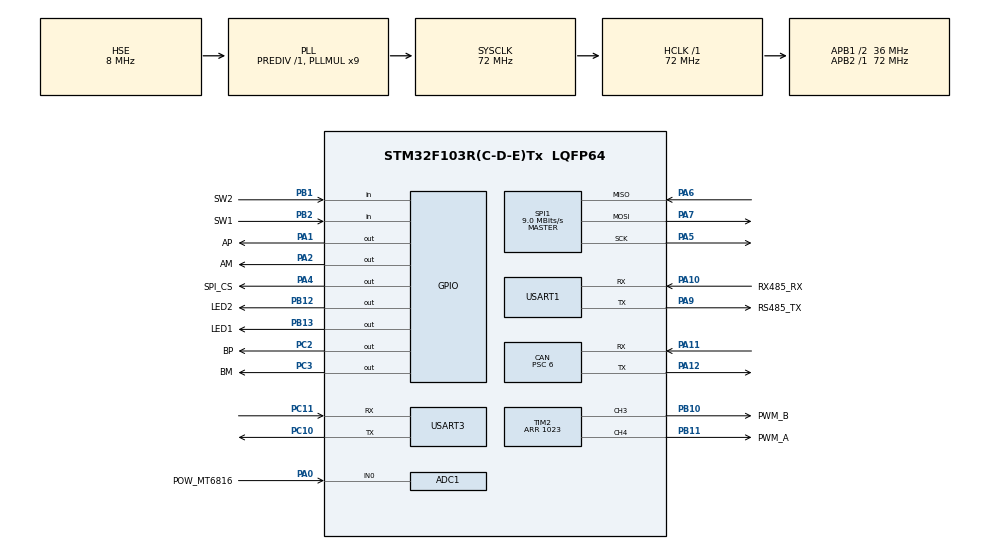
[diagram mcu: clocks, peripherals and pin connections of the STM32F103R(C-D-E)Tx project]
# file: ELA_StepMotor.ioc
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ADC1.Channel-0\#ChannelRegularConversion=ADC_CHANNEL_0
ADC1.NbrOfConversionFlag=1
ADC1.Rank-0\#ChannelRegularConversion=1
ADC1.SamplingTime-0\#ChannelRegularConversion=ADC_SAMPLETIME_1CYCLE_5
ADC1.master=1
CAN.BS1=CAN_BS1_9TQ
CAN.BS2=CAN_BS2_2TQ
CAN.CalculateBaudRate=499999
CAN.CalculateTimeBit=2000
CAN.CalculateTimeQuantum=166.66666666666669
CAN.Prescaler=6
CAN.SJW=CAN_SJW_1TQ
Dma.ADC1.0.Direction=DMA_PERIPH_TO_MEMORY
Dma.ADC1.0.Instance=DMA1_Channel1
Dma.ADC1.0.MemDataAlignment=DMA_MDATAALIGN_HALFWORD
Dma.ADC1.0.MemInc=DMA_MINC_ENABLE
Dma.ADC1.0.Mode=DMA_CIRCULAR
Dma.ADC1.0.PeriphDataAlignment=DMA_PDATAALIGN_HALFWORD
Dma.ADC1.0.PeriphInc=DMA_PINC_DISABLE
Dma.ADC1.0.Priority=DMA_PRIORITY_VERY_HIGH
Dma.Request0=ADC1
Dma.Request1=USART3_RX
Dma.Request2=USART3_TX
Dma.Request3=USART1_RX
Dma.Request4=USART1_TX
Dma.USART1_RX.3.Direction=DMA_PERIPH_TO_MEMORY
Dma.USART1_RX.3.Instance=DMA1_Channel5
Dma.USART1_RX.3.MemDataAlignment=DMA_MDATAALIGN_BYTE
Dma.USART1_RX.3.MemInc=DMA_MINC_ENABLE
Dma.USART1_RX.3.Mode=DMA_CIRCULAR
Dma.USART1_RX.3.PeriphDataAlignment=DMA_PDATAALIGN_BYTE
Dma.USART1_RX.3.PeriphInc=DMA_PINC_DISABLE
Dma.USART1_RX.3.Priority=DMA_PRIORITY_HIGH
Dma.USART1_TX.4.Direction=DMA_MEMORY_TO_PERIPH
Dma.USART1_TX.4.Instance=DMA1_Channel4
Dma.USART1_TX.4.MemDataAlignment=DMA_MDATAALIGN_BYTE
Dma.USART1_TX.4.MemInc=DMA_MINC_ENABLE
Dma.USART1_TX.4.Mode=DMA_NORMAL
Dma.USART1_TX.4.PeriphDataAlignment=DMA_PDATAALIGN_BYTE
Dma.USART1_TX.4.PeriphInc=DMA_PINC_DISABLE
Dma.USART1_TX.4.Priority=DMA_PRIORITY_HIGH
Dma.USART3_RX.1.Direction=DMA_PERIPH_TO_MEMORY
Dma.USART3_RX.1.Instance=DMA1_Channel3
Dma.USART3_RX.1.MemDataAlignment=DMA_MDATAALIGN_BYTE
Dma.USART3_RX.1.MemInc=DMA_MINC_ENABLE
Dma.USART3_RX.1.Mode=DMA_CIRCULAR
Dma.USART3_RX.1.PeriphDataAlignment=DMA_PDATAALIGN_BYTE
Dma.USART3_RX.1.PeriphInc=DMA_PINC_DISABLE
Dma.USART3_RX.1.Priority=DMA_PRIORITY_VERY_HIGH
Dma.USART3_TX.2.Direction=DMA_MEMORY_TO_PERIPH
Dma.USART3_TX.2.Instance=DMA1_Channel2
Dma.USART3_TX.2.MemDataAlignment=DMA_MDATAALIGN_BYTE
Dma.USART3_TX.2.MemInc=DMA_MINC_ENABLE
Dma.USART3_TX.2.Mode=DMA_NORMAL
Dma.USART3_TX.2.PeriphDataAlignment=DMA_PDATAALIGN_BYTE
Dma.USART3_TX.2.PeriphInc=DMA_PINC_DISABLE
Dma.USART3_TX.2.Priority=DMA_PRIORITY_HIGH
Mcu.Family=STM32F1
Mcu.Name=STM32F103R(C-D-E)Tx
Mcu.Package=LQFP64
NVIC.CAN1_RX1_IRQn=true\:0\:0\:false\:false\:true\:true\:true\:true
NVIC.CAN1_SCE_IRQn=true\:0\:0\:false\:false\:true\:true\:true\:true
NVIC.DMA1_Channel1_IRQn=true\:0\:0\:false\:false\:true\:false\:true\:true
NVIC.DMA1_Channel2_IRQn=true\:0\:0\:false\:false\:true\:false\:true\:true
NVIC.DMA1_Channel3_IRQn=true\:0\:0\:false\:false\:true\:false\:true\:true
NVIC.DMA1_Channel4_IRQn=true\:0\:0\:false\:false\:true\:false\:true\:true
NVIC.DMA1_Channel5_IRQn=true\:0\:0\:false\:false\:true\:false\:true\:true
NVIC.PriorityGroup=NVIC_PRIORITYGROUP_4
NVIC.TIM1_UP_IRQn=true\:0\:0\:false\:false\:true\:true\:true\:true
NVIC.TIM3_IRQn=true\:2\:0\:true\:false\:true\:true\:true\:true
NVIC.TIM4_IRQn=true\:0\:0\:false\:false\:true\:true\:true\:true
NVIC.USART1_IRQn=true\:0\:0\:false\:false\:true\:true\:true\:true
NVIC.USART3_IRQn=true\:0\:0\:false\:false\:true\:true\:true\:true
NVIC.USB_HP_CAN1_TX_IRQn=true\:0\:0\:false\:false\:true\:true\:true\:true
NVIC.USB_LP_CAN1_RX0_IRQn=true\:0\:0\:false\:false\:true\:true\:true\:true
PA0-WKUP.GPIO_Label=POW_MT6816
PA0-WKUP.Signal=ADCx_IN0
PA1.GPIO_Label=AP
PA1.Signal=GPIO_Output
PA10.GPIO_Label=RX485_RX
PA10.Mode=Asynchronous
PA10.Signal=USART1_RX
PA11.Mode=CAN_Activate
PA11.Signal=CAN_RX
PA12.Mode=CAN_Activate
PA12.Signal=CAN_TX
PA13.Mode=Serial_Wire
PA13.Signal=SYS_JTMS-SWDIO
PA14.Mode=Serial_Wire
PA14.Signal=SYS_JTCK-SWCLK
PA2.GPIO_Label=AM
PA2.Signal=GPIO_Output
PA4.GPIO_Label=SPI_CS
PA4.GPIO_Speed=GPIO_SPEED_FREQ_HIGH
PA4.Signal=GPIO_Output
PA5.Mode=Full_Duplex_Master
PA5.Signal=SPI1_SCK
PA6.Mode=Full_Duplex_Master
PA6.Signal=SPI1_MISO
PA7.Mode=Full_Duplex_Master
PA7.Signal=SPI1_MOSI
PA9.GPIO_Label=RS485_TX
PA9.Mode=Asynchronous
PA9.Signal=USART1_TX
PB1.GPIO_Label=SW2
PB1.Signal=GPIO_Input
PB10.GPIO_Label=PWM_B
PB10.Signal=S_TIM2_CH3
PB11.GPIO_Label=PWM_A
PB11.Signal=S_TIM2_CH4
PB12.GPIO_Label=LED2
PB12.Signal=GPIO_Output
PB13.GPIO_Label=LED1
PB13.Signal=GPIO_Output
PB2.GPIO_Label=SW1
PB2.Signal=GPIO_Input
PC10.Mode=Asynchronous
PC10.Signal=USART3_TX
PC11.Mode=Asynchronous
PC11.Signal=USART3_RX
PC2.GPIO_Label=BP
PC2.Signal=GPIO_Output
PC3.GPIO_Label=BM
PC3.Signal=GPIO_Output
PD0-OSC_IN.Mode=HSE-External-Oscillator
PD0-OSC_IN.Signal=RCC_OSC_IN
PD1-OSC_OUT.Mode=HSE-External-Oscillator
PD1-OSC_OUT.Signal=RCC_OSC_OUT
ProjectManager.HeapSize=0x200
ProjectManager.StackSize=0x400
ProjectManager.TargetToolchain=MDK-ARM V5.32
RCC.ADCPresc=RCC_ADCPCLK2_DIV6
RCC.AHBFreq_Value=72000000
RCC.APB1CLKDivider=RCC_HCLK_DIV2
RCC.APB1Freq_Value=36000000
RCC.APB1TimFreq_Value=72000000
RCC.APB2Freq_Value=72000000
RCC.APB2TimFreq_Value=72000000
RCC.HCLKFreq_Value=72000000
RCC.PLLMUL=RCC_PLL_MUL9
RCC.PLLSourceVirtual=RCC_PLLSOURCE_HSE
RCC.SYSCLKFreq_VALUE=72000000
RCC.SYSCLKSource=RCC_SYSCLKSOURCE_PLLCLK
RCC.USBFreq_Value=72000000
SH.ADCx_IN0.0=ADC1_IN0,IN0
SH.S_TIM2_CH3.0=TIM2_CH3,PWM Generation3 CH3
SH.S_TIM2_CH4.0=TIM2_CH4,PWM Generation4 CH4
SPI1.BaudRatePrescaler=SPI_BAUDRATEPRESCALER_8
SPI1.CLKPhase=SPI_PHASE_2EDGE
SPI1.CLKPolarity=SPI_POLARITY_HIGH
SPI1.CalculateBaudRate=9.0 MBits/s
SPI1.DataSize=SPI_DATASIZE_16BIT
SPI1.Direction=SPI_DIRECTION_2LINES
SPI1.Mode=SPI_MODE_MASTER
SPI1.VirtualType=VM_MASTER
TIM1.AutoReloadPreload=TIM_AUTORELOAD_PRELOAD_ENABLE
TIM1.Period=9999
TIM1.Prescaler=71
TIM2.Channel-PWM\ Generation3\ CH3=TIM_CHANNEL_3
TIM2.Channel-PWM\ Generation4\ CH4=TIM_CHANNEL_4
TIM2.Period=1023
TIM3.Period=35
TIM3.Prescaler=3599
TIM4.AutoReloadPreload=TIM_AUTORELOAD_PRELOAD_ENABLE
TIM4.Period=49
TIM4.Prescaler=71
USART1.VirtualMode=VM_ASYNC
USART3.VirtualMode=VM_ASYNC
VP_TIM1_VS_ClockSourceINT.Mode=Internal
VP_TIM2_VS_ClockSourceINT.Mode=Internal
VP_TIM3_VS_ClockSourceINT.Mode=Internal
VP_TIM4_VS_ClockSourceINT.Mode=Internal
board=custom

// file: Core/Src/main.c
/* USER CODE BEGIN Header */
/**
  ******************************************************************************
  * @file           : main.c
  * @brief          : Main program body
  ******************************************************************************
  * @attention
  *
  * Copyright (c) 2026 STMicroelectronics.
  * All rights reserved.
  *
  * This software is licensed under terms that can be found in the LICENSE file
  * in the root directory of this software component.
  * If no LICENSE file comes with this software, it is provided AS-IS.
  *
  ******************************************************************************
  */
/* USER CODE END Header */
#include "main.h"
#include "adc.h"
#include "can.h"
#include "dma.h"
#include "spi.h"
#include "tim.h"
#include "usart.h"
#include "gpio.h"

/* USER CODE BEGIN Includes */
#include "elaco_main.h"
/* USER CODE END Includes */

void SystemClock_Config(void);

int main(void)
{

  /* MCU Configuration--------------------------------------------------------*/

  /* Reset of all peripherals, Initializes the Flash interface and the Systick. */
  HAL_Init();

  /* Configure the system clock */
  SystemClock_Config();

  /* Initialize all configured peripherals */
  MX_GPIO_Init();
  MX_DMA_Init();
  MX_ADC1_Init();
  MX_CAN_Init();
  MX_SPI1_Init();
  MX_TIM1_Init();
  MX_TIM2_Init();
  MX_TIM4_Init();
  MX_USART1_UART_Init();
  MX_USART3_UART_Init();
  MX_TIM3_Init();
  /* USER CODE BEGIN 2 */
	elaco_main();
  /* USER CODE END 2 */

  /* Infinite loop */
  while (1)
  {

  }
}

void SystemClock_Config(void)
{
  RCC_OscInitTypeDef RCC_OscInitStruct = {0};
  RCC_ClkInitTypeDef RCC_ClkInitStruct = {0};
  RCC_PeriphCLKInitTypeDef PeriphClkInit = {0};

  /** Initializes the RCC Oscillators according to the specified parameters
  * in the RCC_OscInitTypeDef structure.
  */
  RCC_OscInitStruct.OscillatorType = RCC_OSCILLATORTYPE_HSE;
  RCC_OscInitStruct.HSEState = RCC_HSE_ON;
  RCC_OscInitStruct.HSEPredivValue = RCC_HSE_PREDIV_DIV1;
  RCC_OscInitStruct.HSIState = RCC_HSI_ON;
  RCC_OscInitStruct.PLL.PLLState = RCC_PLL_ON;
  RCC_OscInitStruct.PLL.PLLSource = RCC_PLLSOURCE_HSE;
  RCC_OscInitStruct.PLL.PLLMUL = RCC_PLL_MUL9;
  if (HAL_RCC_OscConfig(&RCC_OscInitStruct) != HAL_OK)
  {
    Error_Handler();
  }

  /** Initializes the CPU, AHB and APB buses clocks
  */
  RCC_ClkInitStruct.ClockType = RCC_CLOCKTYPE_HCLK|RCC_CLOCKTYPE_SYSCLK
                              |RCC_CLOCKTYPE_PCLK1|RCC_CLOCKTYPE_PCLK2;
  RCC_ClkInitStruct.SYSCLKSource = RCC_SYSCLKSOURCE_PLLCLK;
  RCC_ClkInitStruct.AHBCLKDivider = RCC_SYSCLK_DIV1;
  RCC_ClkInitStruct.APB1CLKDivider = RCC_HCLK_DIV2;
  RCC_ClkInitStruct.APB2CLKDivider = RCC_HCLK_DIV1;

  if (HAL_RCC_ClockConfig(&RCC_ClkInitStruct, FLASH_LATENCY_2) != HAL_OK)
  {
    Error_Handler();
  }
  PeriphClkInit.PeriphClockSelection = RCC_PERIPHCLK_ADC;
  PeriphClkInit.AdcClockSelection = RCC_ADCPCLK2_DIV6;
  if (HAL_RCCEx_PeriphCLKConfig(&PeriphClkInit) != HAL_OK)
  {
    Error_Handler();
  }
}

void Error_Handler(void)
{
  __disable_irq();
  while (1)
  {
  }
}
